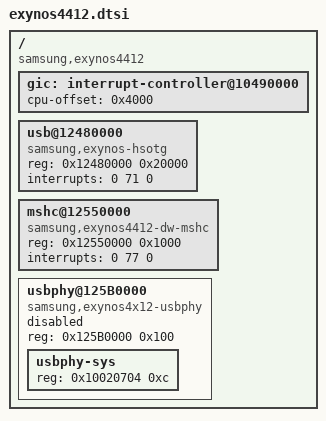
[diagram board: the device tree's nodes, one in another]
/*
 * Samsung's Exynos4412 SoC device tree source
 *
 * Copyright (c) 2012 Samsung Electronics Co., Ltd.
 *		http://www.samsung.com
 *
 * Samsung's Exynos4412 SoC device nodes are listed in this file. Exynos4412
 * based board files can include this file and provide values for board specfic
 * bindings.
 *
 * Note: This file does not include device nodes for all the controllers in
 * Exynos4412 SoC. As device tree coverage for Exynos4412 increases, additional
 * nodes can be added to this file.
 *
 * This program is free software; you can redistribute it and/or modify
 * it under the terms of the GNU General Public License version 2 as
 * published by the Free Software Foundation.
*/

/include/ "exynos4x12.dtsi"

/ {
	compatible = "samsung,exynos4412";

	gic:interrupt-controller@10490000 {
		cpu-offset = <0x4000>;
	};

	usb@12480000 {
		compatible = "samsung,exynos-hsotg";
		reg = <0x12480000 0x20000>;
		interrupts = <0 71 0>;
	};

	mshc@12550000 {
		compatible = "samsung,exynos4412-dw-mshc";
		reg = <0x12550000 0x1000>;
		interrupts = <0 77 0>;
		#address-cells = <1>;
		#size-cells = <0>;
	};

	usbphy@125B0000 {
		#address-cells = <1>;
		#size-cells = <1>;
		compatible = "samsung,exynos4x12-usbphy";
		reg = <0x125B0000 0x100>;
		status = "disabled";
		ranges;

		usbphy-sys {
			reg = <0x10020704 0xc>;
		};
	};
};
